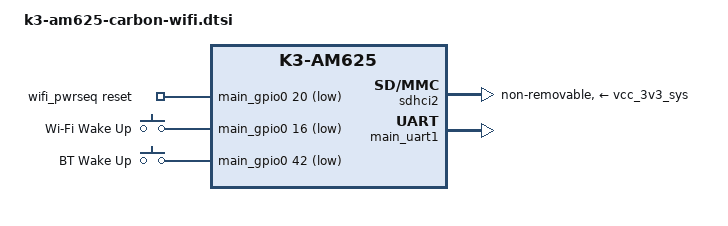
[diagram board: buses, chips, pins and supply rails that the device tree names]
// SPDX-License-Identifier: GPL-2.0
/*
 * SDIO Wi-Fi module
 * Copyright (C) 2024 Ezurio LLC
 */

#include <dt-bindings/input/input.h>

/ {
	wifi_pwrseq: wifi-pwrseq {
		compatible = "mmc-pwrseq-simple";

		pinctrl-names = "default";
		pinctrl-0 = <&main_wifi_en_default>;
		reset-gpios = <&main_gpio0 20 GPIO_ACTIVE_LOW>;

		power-off-delay-us = <100000>;
		post-power-on-delay-ms = <150>;

		clocks = <&rv3028>;
		clock-names = "ext_clock";
		// Store the clock rate and enable in the EEPROM
		// so it comes up on power up
		assigned-clocks = <&rv3028>;
		assigned-clock-rates = <32768>;
	};

	wifi_wakeup: wifi_wakeup {
		compatible = "gpio-keys";

		pinctrl-names = "default";
		pinctrl-0 = <&main_wifi_wake_default>, <&main_bt_wake_pins_default>;

		wifi-wake-up {
			label = "Wi-Fi Wake Up";
			gpios = <&main_gpio0 16 GPIO_ACTIVE_LOW>;
			linux,code = <KEY_WAKEUP>;
			wakeup-source;
		};

		bt-wake-up {
			label = "BT Wake Up";
			gpios = <&main_gpio0 42 GPIO_ACTIVE_LOW>;
			linux,code = <KEY_WAKEUP>;
			wakeup-source;
		};
	};
};

&sdhci2 { /* SDIO_B  WIFI */
	status = "okay";

	pinctrl-names = "default";
	pinctrl-0 = <&main_mmc2_pins_default>;

	vmmc-supply = <&vcc_3v3_sys>;
	mmc-pwrseq = <&wifi_pwrseq>;

	non-removable;
	ti,fails-without-test-cd;
	ti,driver-strength-ohm = <50>;
	keep-power-in-suspend;

	#address-cells = <1>;
	#size-cells = <0>;
};

&main_uart1 {
	status = "okay";

	uart-has-rtscts;
};
